# ATxmega256A3BU device description
Architecture: AVR8_XMEGA; Family: AVR XMEGA
Registers are 8-bit, access not given, no defined reset value unless marked. A register's access mark holds for its fields unless they carry their own. Offsets are from the block's base; [hi:lo] are bit positions; {n}, {i} and the like mark numbered series; 'fields as' and 'values as' point back to an identical list.

## VBAT — Battery Backup Module
Instances: VBAT 0x0F0
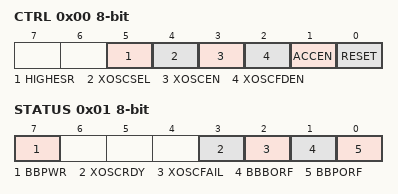
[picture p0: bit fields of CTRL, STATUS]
0x00 CTRL — Control Register
  [5] HIGHESR — 32-kHz Crystal Oscillator High Power Mode
  [4] XOSCSEL — 32-kHz Crystal Oscillator Output Selection
  [3] XOSCEN — Crystal Oscillator Enable
  [2] XOSCFDEN — Crystal Oscillator Failure Detection Monitor Enable
  [1] ACCEN — Access Enable
  [0] RESET
0x01 STATUS
  [7] BBPWR — Battery backup Power
  [3] XOSCRDY — Crystal Oscillator Ready
  [2] XOSCFAIL — Crystal Oscillator Failure
  [1] BBBORF — Battery Backup Brown-Out Reset Flag
  [0] BBPORF — Battery Backup Power-On Reset Flag
0x02 BACKUP0 — Backup Register 0
0x03 BACKUP1 — Backup Register 1

## DMA — DMA Controller
Instances: DMA 0x0100
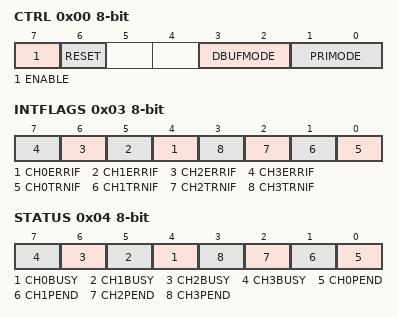
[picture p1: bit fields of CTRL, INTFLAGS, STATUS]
0x00 CTRL — Control
  [7] ENABLE
  [6] RESET — Software Reset
  [3:2] DBUFMODE — Double Buffering Mode
    0=DISABLED (Double buffering disabled); 1=CH01 (Double buffering enabled on channel 0/1); 2=CH23 (Double buffering enabled on channel 2/3); 3=CH01CH23 (Double buffering enabled on ch. 0/1 and ch. 2/3)
  [1:0] PRIMODE — Channel Priority Mode
    0=RR0123 (Round Robin); 1=CH0RR123 (Channel 0 > Round Robin on channel 1/2/3); 2=CH01RR23 (Channel 0 > channel 1 > Round Robin on channel 2/3); 3=CH0123 (Channel 0 > channel 1 > channel 2 > channel 3)
0x03 INTFLAGS — Transfer Interrupt Status
  [n+4] CH{n}ERRIF (n=0..3) — Channel {n} Block Transfer Error Interrupt Flag
  [n] CH{n}TRNIF (n=0..3) — Channel {n} Transaction Complete Interrupt Flag
0x04 STATUS
  [n+4] CH{n}BUSY (n=0..3) — Channel {n} Block Transfer Busy
  [n] CH{n}PEND (n=0..3) — Channel {n} Block Transfer Pending
0x06 TEMP 16-bit — Temporary Register For 16/24-bit Access

## NVM — Non-volatile Memory Controller
Instances: NVM 0x01C0
{0x0+i} ADDR{i} (i=0..2) — Address Register {i}
{0x4+i} DATA{i} (i=0..2) — Data Register {i}
0x0A CMD — Command
  [6:0] CMD
    0=NO_OPERATION (Noop/Ordinary LPM); 1=READ_USER_SIG_ROW (Read user signature row); 2=READ_CALIB_ROW (Read calibration row); 6=READ_EEPROM; 7=READ_FUSES (Read fuse byte); 8=WRITE_LOCK_BITS; 24=ERASE_USER_SIG_ROW (Erase user signature row); 26=WRITE_USER_SIG_ROW (Write user signature row); 32=ERASE_APP (Erase Application Section); 34=ERASE_APP_PAGE (Erase Application Section page); 35=LOAD_FLASH_BUFFER (Load Flash page buffer); 36=WRITE_APP_PAGE (Write Application Section page); 37=ERASE_WRITE_APP_PAGE (Erase-and-write Application Section page); 38=ERASE_FLASH_BUFFER (Erase/flush Flash page buffer); 42=ERASE_BOOT_PAGE (Erase Boot Section page); 43=ERASE_FLASH_PAGE; 44=WRITE_BOOT_PAGE (Write Boot Section page); 45=ERASE_WRITE_BOOT_PAGE (Erase-and-write Boot Section page); 46=WRITE_FLASH_PAGE; 47=ERASE_WRITE_FLASH_PAGE (Erase-and-write Flash Page); 48=ERASE_EEPROM; 50=ERASE_EEPROM_PAGE; 51=LOAD_EEPROM_BUFFER (Load EEPROM page buffer); 52=WRITE_EEPROM_PAGE; 53=ERASE_WRITE_EEPROM_PAGE (Erase-and-write EEPROM page); 54=ERASE_EEPROM_BUFFER (Erase/flush EEPROM page buffer); 56=APP_CRC (Application section CRC); 57=BOOT_CRC (Boot Section CRC); 58=FLASH_RANGE_CRC; 64=CHIP_ERASE (Erase Chip); 67=READ_NVM; 76=WRITE_FUSE (Write Fuse byte); 104=ERASE_BOOT (Erase Boot Section); 120=FLASH_CRC
0x0B CTRLA — Control Register A
  [0] CMDEX — Command Execute
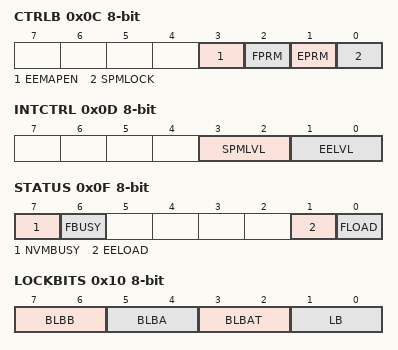
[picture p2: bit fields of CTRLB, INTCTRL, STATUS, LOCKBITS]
0x0C CTRLB — Control Register B
  [3] EEMAPEN — EEPROM Mapping Enable
  [2] FPRM — Flash Power Reduction Enable
  [1] EPRM — EEPROM Power Reduction Enable
  [0] SPMLOCK
0x0D INTCTRL — Interrupt Control
  [3:2] SPMLVL — SPM Interrupt Level
    0=OFF (Interrupt disabled); 1=LO (Low level); 2=MED (Medium level); 3=HI (High level)
  [1:0] EELVL — EEPROM Interrupt Level
    values as SPMLVL
0x0F STATUS
  [7] NVMBUSY — Non-volatile Memory Busy
  [6] FBUSY — Flash Memory Busy
  [1] EELOAD — EEPROM Page Buffer Active Loading
  [0] FLOAD — Flash Page Buffer Active Loading
0x10 LOCKBITS
  [7:6] BLBB — Boot Lock Bits - Boot Section
    0=RWLOCK (Read and write not allowed); 1=RLOCK (Read not allowed); 2=WLOCK (Write not allowed); 3=NOLOCK (No locks)
  [5:4] BLBA — Boot Lock Bits - Application Section
    values as BLBB
  [3:2] BLBAT — Boot Lock Bits - Application Table
    values as BLBB
  [1:0] LB — Lock Bits
    0=RWLOCK (Read and write not allowed); 2=WLOCK (Write not allowed); 3=NOLOCK (No locks)
